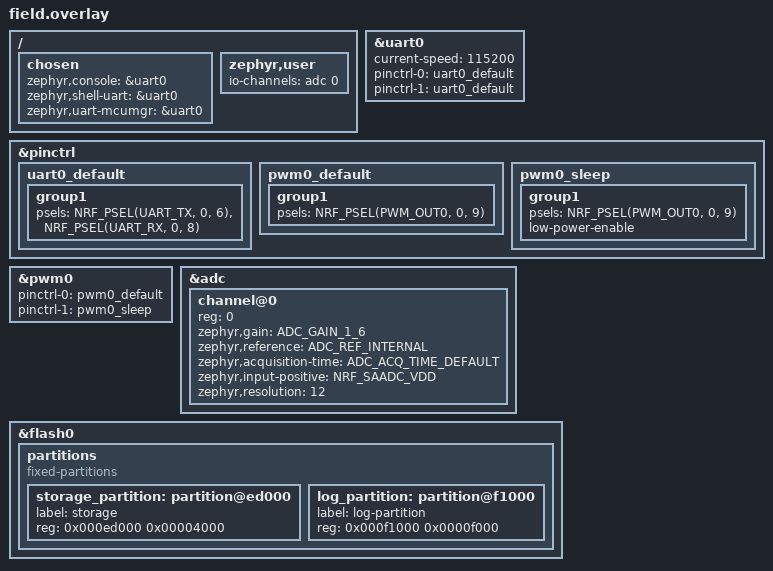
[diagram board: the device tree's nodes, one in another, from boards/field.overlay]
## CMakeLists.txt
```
cmake_minimum_required(VERSION 3.20.0)
find_package(Zephyr REQUIRED HINTS $ENV{ZEPHYR_BASE})
project(reed_sensor)

target_sources(app PRIVATE
    src/main.c
    src/reed_hw_zephyr.c
    src/ble_adv.c
    src/battery.c
    src/build_info.c
    src/trinity_wdt.c
    src/trinity_canary.c
    src/trinity_flash.c
    src/trinity_stats.c
    src/trinity_fault.c
    src/trinity_boot.c
    drivers/fuel_gauge/max17048/max17048.c
)

target_include_directories(app PRIVATE
    drivers/fuel_gauge/max17048
    ../../include
)
```

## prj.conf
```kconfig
# /******************************************************************************
# * \file prj.conf
# * \author MichaelLynnCSU (https://github.com/MichaelLynnCSU)
# * \date    01-01-2025
# *
# * \brief   Zephyr project configuration for nRF52840 reed sensor node.
# *
# * \details Enables GPIO, ADC, UART console, deferred logging, BLE
# *          broadcaster/observer, flash storage, UF2 build output,
# *          stack sentinel, and heap checking for trinity fault coverage.
# *
# *          Trinity build mode is selected at west build time:
# *            BENCH: west build -- -DCONFIG_TRINITY_MODE_BENCH=y
# *            FIELD: west build (default — no extra flag needed)
# ******************************************************************************/

# ========================= CORE PERIPHERALS ==================================
CONFIG_GPIO=y
CONFIG_ADC=y
CONFIG_PRINTK=y

# ========================= CONSOLE / UART ====================================
CONFIG_CONSOLE=y
CONFIG_UART_CONSOLE=y
CONFIG_UART_INTERRUPT_DRIVEN=y

# ========================= LOGGING ===========================================
CONFIG_LOG=y
CONFIG_LOG_BACKEND_UART=y
CONFIG_LOG_MODE_DEFERRED=y
CONFIG_LOG_DEFAULT_LEVEL=3
CONFIG_LOG_BUFFER_SIZE=16384
CONFIG_BT_LOG_LEVEL_OFF=y

# ========================= BLUETOOTH =========================================
CONFIG_BT=y
CONFIG_BT_PERIPHERAL=y
CONFIG_BT_BROADCASTER=y
CONFIG_BT_OBSERVER=y
CONFIG_BT_SMP=y
CONFIG_BT_PRIVACY=n
CONFIG_BT_GATT_SERVICE_CHANGED=n
CONFIG_BT_DEVICE_NAME="ReedSensor"

# ========================= FLASH STORAGE =====================================
CONFIG_FLASH=y
CONFIG_FLASH_MAP=y
CONFIG_FLASH_PAGE_LAYOUT=y
CONFIG_MPU_ALLOW_FLASH_WRITE=y
CONFIG_STREAM_FLASH=y

# ========================= BUILD OUTPUT ======================================
CONFIG_BUILD_OUTPUT_UF2=y

# ========================= PERSISTENT SETTINGS ===============================
CONFIG_BT_SETTINGS=y
CONFIG_NVS=y
CONFIG_SETTINGS=y
CONFIG_SETTINGS_NVS=y

# ========================= FAULT COVERAGE ====================================
CONFIG_REBOOT=y
CONFIG_FAULT_DUMP=2
CONFIG_FRAME_POINTER=y
CONFIG_HW_STACK_PROTECTION=y
CONFIG_HEAP_MEM_POOL_IGNORE_MIN=y
CONFIG_THREAD_STACK_INFO=y
CONFIG_THREAD_NAME=y
CONFIG_INIT_STACKS=y

# ========================= RADIO / FLASH SYNC ================================
CONFIG_SOC_FLASH_NRF_RADIO_SYNC_TICKER=y

# ========================= TRINITY WATCHDOG ==================================
CONFIG_WATCHDOG=y
CONFIG_WDT_DISABLE_AT_BOOT=n

# ========================= TRINITY HEAP STATS ================================
CONFIG_SYS_HEAP_RUNTIME_STATS=y
CONFIG_HEAP_MEM_POOL_SIZE=4096
CONFIG_HEAP_MEM_POOL_IGNORE_MIN=y

# ========================= TRINITY THREAD STATS ==============================
CONFIG_THREAD_ANALYZER=y
CONFIG_THREAD_ANALYZER_USE_PRINTK=n
CONFIG_THREAD_ANALYZER_AUTO=n
CONFIG_THREAD_RUNTIME_STATS=y

# ========================= STACK SIZES =======================================
CONFIG_SYSTEM_WORKQUEUE_STACK_SIZE=3072
CONFIG_MAIN_STACK_SIZE=2048
CONFIG_ISR_STACK_SIZE=4096
CONFIG_BOOT_DELAY=2000
CONFIG_LOG_PROCESS_THREAD_STACK_SIZE=2048

# ========================= I2C / FUEL GAUGE ==================================
CONFIG_I2C=y
CONFIG_I2C_NRFX=y
CONFIG_FUEL_GAUGE=y
CONFIG_MAX17048=n
CONFIG_MAX17048=n
```

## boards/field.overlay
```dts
/*******************************************************************************
 * \file field.overlay
 * \author MichaelLynnCSU (https://github.com/MichaelLynnCSU)
 * \date 01-01-2025
 *
 * \brief Field mode devicetree overlay for Pro Micro nRF52840 reed sensor.
 *
 * \details Configures UART console on P0.06/P0.08. Battery measurement
 *          handled by MAX17048 fuel gauge IC over I2C. See
 *          promicro_nrf52840.overlay for full SAADC failure history.
 *
 * \note    Enable pin removed (2026-03-29):
 *          P0.29 vbat-div-en node removed. Pin was wired to P0.31 not
 *          Vbat and had no effect.
 *
 * \note    BATTERY ADC HISTORY (2026-04-22):
 *          All SAADC-based battery measurement approaches failed on this
 *          board due to the HX3001 LDO permanently separating the CR2032
 *          from VDD. Four approaches tested -- see promicro_nrf52840.overlay
 *          for complete failure analysis. Current solution is MAX17048
 *          fuel gauge IC measuring B+ directly over I2C.
 *
 *          Short summary of what was tried and why it failed:
 *          - Divider + AIN:      worked but attenuated a voltage already
 *                                in range. Retained as fallback only.
 *          - Direct AIN:         CR2032 impedance (10-30 ohm) collapses
 *                                under SAADC input capacitance load.
 *          - NRF_SAADC_VDD:      reads 2.5V regulated rail, not cell.
 *          - Direct AIN + caps:  2x 10uF insufficient. CR2032 cannot
 *                                recharge caps fast enough. Datasheet cap
 *                                recommendation assumes low-impedance source,
 *                                not CR2032. Hundreds of uF would be needed.
 *                                Radio state is not the determining factor --
 *                                fails with radio idle too.
 *******************************************************************************/
/delete-node/ &storage_partition;

/ {
    chosen {
        zephyr,console = &uart0;
        zephyr,shell-uart = &uart0;
        zephyr,uart-mcumgr = &uart0;
    };

    zephyr,user {
        io-channels = <&adc 0>;
    };
};

&uart0 {
    status = "okay";
    current-speed = <115200>;
    pinctrl-0 = <&uart0_default>;
    pinctrl-1 = <&uart0_default>;
    pinctrl-names = "default", "sleep";
};

&pinctrl {
    uart0_default: uart0_default {
        group1 {
            psels = <NRF_PSEL(UART_TX, 0, 6)>,
                    <NRF_PSEL(UART_RX, 0, 8)>;
        };
    };
    pwm0_default: pwm0_default {
        group1 {
            psels = <NRF_PSEL(PWM_OUT0, 0, 9)>;
        };
    };
    pwm0_sleep: pwm0_sleep {
        group1 {
            psels = <NRF_PSEL(PWM_OUT0, 0, 9)>;
            low-power-enable;
        };
    };
};

&pwm0 {
    status = "okay";
    pinctrl-0 = <&pwm0_default>;
    pinctrl-1 = <&pwm0_sleep>;
    pinctrl-names = "default", "sleep";
};

&adc {
    status = "okay";
    #address-cells = <1>;
    #size-cells = <0>;
    channel@0 {
        reg = <0>;
        zephyr,gain = "ADC_GAIN_1_6";
        zephyr,reference = "ADC_REF_INTERNAL";
        zephyr,acquisition-time = <ADC_ACQ_TIME_DEFAULT>;
        zephyr,input-positive = <NRF_SAADC_VDD>; /* reads regulated 2.5V rail --
                                                     retained for reference only,
                                                     MAX17048 handles cell measurement */
        zephyr,resolution = <12>;
    };
};

&flash0 {
    partitions {
        compatible = "fixed-partitions";
        #address-cells = <1>;
        #size-cells = <1>;
        storage_partition: partition@ed000 {
            label = "storage";
            reg = <0x000ed000 0x00004000>;
        };
        log_partition: partition@f1000 {
            label = "log-partition";
            reg = <0x000f1000 0x0000f000>;
        };
    };
};
```

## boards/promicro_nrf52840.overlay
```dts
/*******************************************************************************
 * \file promicro_nrf52840.overlay
 * \author MichaelLynnCSU (https://github.com/MichaelLynnCSU)
 * \date 01-01-2025
 *
 * \brief Devicetree overlay for Pro Micro nRF52840 reed sensor node.
 *
 * \details Configures:
 *          - ADC channel 0: VDD internal monitor, 12-bit, 1/6 gain
 *          - UART0: TX=P0.06, RX=P0.08 (overrides board default P0.09/P0.10)
 *          - Flash partitions:
 *            storage_partition @ 0xED000 (16KB) NVS settings
 *            log_partition     @ 0xF1000 (16KB) flash event log
 *
 * \warning Deletes the default storage_partition and redefines it
 *          alongside log_partition in the upper flash region.
 *
 * \note    UART pin override (2026-03-29):
 *          Board default (promicro_nrf52840-pinctrl.dtsi) is TX=P0.09,
 *          RX=P0.10. Overridden here to TX=P0.06, RX=P0.08 to match
 *          the physical header pins used on this node. Override uses
 *          direct node reference (&uart0_default) instead of wrapping
 *          in &pinctrl {} -- the wrapper caused duplicate label conflicts
 *          with the board dtsi, leaving both pin sets active and the
 *          board defaults winning.
 *
 * \note    BATTERY ADC HISTORY -- DO NOT RETRY THESE APPROACHES (2026-04-22):
 *          This board (Teyleten Robot Pro Micro nRF52840) has a HX3001 LDO
 *          regulator permanently in the power path. CR2032 (3V) → HX3001
 *          → 2.5V VDD. The LDO output is always 2.5V regardless of cell
 *          state. SWD connection does not affect this.
 *
 *          Four SAADC approaches were tested and failed:
 *
 *          TEST 1 -- P0.02 (AIN0) + 200k/100k divider:
 *          Worked but nonsensical. CR2032 max voltage (3V) is already within
 *          SAADC range (3.6V at ADC_GAIN_1_6). Divider attenuated a voltage
 *          that needed no attenuation, wasted resolution, added quiescent
 *          drain. Abandoned in favour of direct connection.
 *          NOTE: This is the only SAADC approach that produced stable
 *          readings. It remains the fallback if MAX17048 is unavailable.
 *
 *          TEST 2 -- P0.02 (AIN0) direct, no divider, no caps:
 *          Failed. CR2032 internal impedance (10-30 ohms) cannot source
 *          the SAADC input capacitance charge current fast enough. Rail
 *          collapses during sampling. Longer acquisition time (40us tested)
 *          made it worse -- more time connected means more charge drawn,
 *          deeper voltage sag. Fails even pre-BLE with radio fully idle.
 *
 *          TEST 3 -- NRF_SAADC_VDD internal monitor:
 *          Failed. NRF_SAADC_VDD measures the VDD rail (2.5V regulated),
 *          not the cell. Nordic recommendation assumes cell IS VDD (no
 *          regulator in path). That assumption does not hold on this board.
 *          Always reads ~1812 mV regardless of cell state.
 *
 *          TEST 4 -- P0.02 (AIN0) direct + 2x 10uF bulk caps:
 *          Failed. Datasheet cap recommendation assumes low-impedance source
 *          (Li-ion, LiPo). CR2032 at 10-30 ohms cannot recharge caps fast
 *          enough between samples. Hundreds of uF would be required --
 *          impractical for a coin cell node. Fails with radio idle and
 *          active. Radio state is not the determining factor.
 *
 *          CURRENT SOLUTION -- MAX17048 fuel gauge IC over I2C:
 *          Measures B+ directly with nanoamp bias current. Independent of
 *          VDD rail, SAADC, and BLE radio. See battery.c for implementation.
 *******************************************************************************/
/delete-node/ &storage_partition;
/ {
    zephyr,user {
        io-channels = <&adc 0>;
    };
};
&uart0_default {
    group1 {
        psels = <NRF_PSEL(UART_TX, 0, 6)>,
                <NRF_PSEL(UART_RX, 0, 8)>;
    };
};
&uart0_sleep {
    group1 {
        psels = <NRF_PSEL(UART_TX, 0, 6)>,
                <NRF_PSEL(UART_RX, 0, 8)>;
        low-power-enable;
    };
};
&adc {
    status = "okay";
    #address-cells = <1>;
    #size-cells = <0>;
    channel@0 {
        reg = <0>;
        zephyr,gain = "ADC_GAIN_1_6";
        zephyr,reference = "ADC_REF_INTERNAL";
        zephyr,acquisition-time = <ADC_ACQ_TIME_DEFAULT>;
        zephyr,input-positive = <NRF_SAADC_VDD>; /* reads regulated 2.5V rail --
                                                     retained for reference only,
                                                     MAX17048 handles cell measurement */
        zephyr,resolution = <12>;
    };
};
&flash0 {
    partitions {
        compatible = "fixed-partitions";
        #address-cells = <1>;
        #size-cells = <1>;
        storage_partition: partition@ed000 {
            label = "storage";
            reg = <0x000ed000 0x00004000>;
        };
        log_partition: partition@f1000 {
            label = "log-partition";
            reg = <0x000f1000 0x00004000>;
        };
    };
};
&uart0 {
    status = "okay";
    current-speed = <115200>;
};
```

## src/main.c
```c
/******************************************************************************
 * \file    main.c
 * \author  MichaelLynnCSU (https://github.com/MichaelLynnCSU)
 * \date    01-01-2025
 *
 * \brief   Reed sensor node entry point for door/window state monitoring.
 *
 * \details Monitors a reed switch via GPIO interrupt and broadcasts
 *          open/closed state over BLE manufacturer data advertisements.
 *          Battery SOC is included in the advertisement payload and
 *          updated every 5 minutes.
 *
 *          Hardware:
 *          - Board:    Pro Micro nRF52840
 *          - Reed pin: GPIO0 pin 11 (active-low, pull-up)
 *          - LED:      DT alias led0
 *          - Battery:  MAX17048 fuel gauge over I2C1 (P1.13 SDA, P1.15 SCL)
 *
 * \note    WDT fix (2026-03-21):
 *          REED_POLL_MS reduced from 10000ms to 2000ms. trinity_wdt_kick()
 *          called before sem_take so WDT is fed even when reed is stable.
 *
 * \note    WDT boot-feed fix (2026-03-22):
 *          Progressive WDT feeding at each boot checkpoint. bt_enable()
 *          and settings_load() can each consume up to 2s of the 3s budget.
 *
 * \note    RESETREAS clear fix (2026-03-27):
 *          RESETREAS read and cleared at very top of main() before any
 *          other code runs. Register is latched OR-history -- must be
 *          explicitly cleared to prevent stale bits surviving across boots.
 *
 * \note    Battery read before BLE (2026-04-22, updated 2026-05-01):
 *          battery_read_soc() called before bt_enable() while VDD is
 *          stable. bt_enable() current spike collapses CR2032 rail and
 *          corrupts SAADC reading. Pre-populated into g_mfg_data via
 *          ble_adv_set_batt() so BLE thread uses it directly. With
 *          MAX17048 the rail collapse is less critical (fuel gauge is
 *          independent of SAADC) but the ordering is retained to ensure
 *          the first advertisement always carries a valid SOC.
 *
 * \note    Battery divider removed (2026-04-22):
 *          Resistor divider physically removed. Vbat connects directly
 *          to P0.02 (AIN0). CR2032 3.0V is within ADC_GAIN_1_6 max
 *          input of 3.6V. No quiescent divider drain.
 ******************************************************************************/

#include <zephyr/kernel.h>
#include <zephyr/drivers/gpio.h>
#include <zephyr/logging/log.h>
#include <nrf.h>
#include <string.h>
#include "reed_hw.h"
#include "ble_adv.h"
#include "battery.h"
#include "trinity_log.h"
#include "main.h"

LOG_MODULE_REGISTER(reed_main, LOG_LEVEL_INF);

#define BLE_STACK_SIZE   4096
#define BLE_PRIORITY     5
#define REED_DEBOUNCE_MS 50

K_SEM_DEFINE(g_reed_changed_sem, 0, 1);

static struct gpio_callback g_reed_cb_data;
static const struct device *g_gpio0_int;

/*----------------------------------------------------------------------------*/

static void reed_interrupt_handler(const struct device *p_dev,
                                    struct gpio_callback *p_cb,
                                    uint32_t pins)
{
    (void)p_dev;
    (void)p_cb;
    (void)pins;

    k_sem_give(&g_reed_changed_sem);
}

/*----------------------------------------------------------------------------*/

static int interrupt_init(void)
{
    int err = 0;

    g_gpio0_int = DEVICE_DT_GET(DT_NODELABEL(gpio0));
    if (!device_is_ready(g_gpio0_int))
    {
        LOG_ERR("GPIO0 not ready for interrupt");
        return -ENODEV;
    }

    err = gpio_pin_interrupt_configure(g_gpio0_int, 11, GPIO_INT_EDGE_BOTH);
    if (0 != err) { LOG_ERR("Reed interrupt configure failed (err=%d)", err); return err; }

    gpio_init_callback(&g_reed_cb_data, reed_interrupt_handler, BIT(11));

    err = gpio_add_callback(g_gpio0_int, &g_reed_cb_data);
    if (0 != err) { LOG_ERR("Reed callback add failed (err=%d)", err); return err; }

    return 0;
}

/*----------------------------------------------------------------------------*/

static void reed_monitor_loop(int last_state)
{
    int     err        = 0;
    int     val        = 0;
    int     batt_tick  = 0;
    int     stats_tick = 0;
    uint8_t cur        = 0;
    uint8_t state      = 0;
    uint8_t soc        = 0;

    while (1)
    {
        trinity_wdt_kick();

        (void)k_sem_take(&g_reed_changed_sem,
                          K_TIMEOUT_ABS_TICKS(
                             k_uptime_ticks() +
                             k_ms_to_ticks_ceil32(REED_POLL_MS)));

        if (++batt_tick >= BATT_UPDATE_TICKS)
        {
            batt_tick = 0;
            soc = battery_read_soc();
            ble_adv_set_batt(soc);
            cur = (uint8_t)reed_hw_read();
            err = k_msgq_put(&g_ble_msgq, &cur, K_NO_WAIT);
            if (0 != err) { LOG_WRN("[BATT] msgq full, drop (err=%d)", err); }
        }

        if (++stats_tick >= STATS_INTERVAL_TICKS)
        {
            stats_tick = 0;
            trinity_log_heap_stats();
            trinity_log_task_stats();
        }

        k_sleep(K_MSEC(REED_DEBOUNCE_MS));

        val = reed_hw_read();
        if (0 > val)
        {
            LOG_WRN("[REED] Pin read failed (err=%d)", val);
        }
        else if (val != last_state)
        {
            LOG_INF("[REED] Changed: %d (%s)", val, val ? "OPEN" : "CLOSED");

            trinity_log_event(val ?
                "EVENT: REED_OPEN\n" : "EVENT: REED_CLOSED\n");

            reed_hw_set_led(!val);

            state = (uint8_t)val;
            err = k_msgq_put(&g_ble_msgq, &state, K_NO_WAIT);
            if (0 != err) { LOG_WRN("[REED] msgq full, drop (err=%d)", err); }

            last_state = val;
        }
    }
}

/*----------------------------------------------------------------------------*/

int main(void)
{
    int      err          = 0;
    int      initial      = 0;
    uint8_t  init_state   = 0;
    uint8_t  soc          = 0;
    uint32_t reset_reason = 0;
    k_tid_t  tid;

    static K_THREAD_STACK_DEFINE(ble_stack, BLE_STACK_SIZE);
    static struct k_thread ble_thread_data;

    reset_reason = NRF_POWER->RESETREAS;
    NRF_POWER->RESETREAS = 0xFFFFFFFF;

#if !defined(CONFIG_TRINITY_MODE_BENCH)
    g_init_stage = TRINITY_STAGE_WDT_INIT;
    trinity_wdt_init();
    trinity_wdt_kick();
#endif

    LOG_INF("=== ReedSensor Boot ===");
    trinity_log_dump_previous();

    if (trinity_log_init() == 0)
    {
        trinity_log_boot_reason(reset_reason);
    }
    trinity_wdt_kick();

    trinity_log_dump_previous_deferred();

#if defined(CONFIG_TRINITY_MODE_BENCH)
    g_init_stage = TRINITY_STAGE_WDT_INIT;
    trinity_wdt_init();
    trinity_wdt_kick();
#endif

    err = reed_hw_init();
    if (0 != err) { return err; }

    err = interrupt_init();
    if (0 != err) { return err; }
    trinity_wdt_kick();

    if (0 != battery_init()) { LOG_WRN("Battery init failed, SOC will read 0"); }
    trinity_wdt_kick();

    soc = battery_read_soc();
    ble_adv_set_batt(soc);
    LOG_INF("Pre-BLE battery mV: %d", battery_read_mv());
    LOG_INF("Pre-BLE battery SOC: %d%%", soc);
    trinity_wdt_kick();

    k_sleep(K_MSEC(100));

    initial = reed_hw_read();
    if (0 > initial) { LOG_ERR("Reed initial read failed (err=%d)", initial); return initial; }

    LOG_INF("Initial state: %d (%s)", initial, initial ? "OPEN" : "CLOSED");

    reed_hw_set_led(initial ? 0 : 1);

    init_state = (uint8_t)initial;
    err = k_msgq_put(&g_ble_msgq, &init_state, K_NO_WAIT);
    if (0 != err) { LOG_WRN("Initial state msgq put failed (err=%d)", err); }

    tid = k_thread_create(&ble_thread_data,
                           ble_stack, BLE_STACK_SIZE,
                           ble_thread,
                           NULL, NULL, NULL,
                           BLE_PRIORITY, 0, K_NO_WAIT);
    if (NULL == tid) { LOG_ERR("BLE thread create failed"); return -ENOMEM; }
    k_thread_name_set(tid, "ble_thread");

    trinity_wdt_kick();

    LOG_INF("BLE thread spawned");
    LOG_INF("Monitoring reed switch");

    reed_monitor_loop(initial);

    return 0;
}
```

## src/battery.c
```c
/******************************************************************************
 * \file battery.c
 * \author MichaelLynnCSU (https://github.com/MichaelLynnCSU)
 * \date 01-01-2025
 *
 * \brief Battery measurement for nRF52840 reed sensor node.
 *
 * \details Reads SOC and voltage from MAX17048 fuel gauge over I2C1
 *          (P1.13 SDA, P1.15 SCL). Uses Zephyr fuel_gauge API.
 *          Returns -1 / 0 on error so callers can store NULL in SQLite.
 *          SOC is clamped to 100 -- ModelGauge reports >100% on fresh
 *          cells until the algorithm settles (~few minutes).
 *
 *          Hardware:
 *          - Board:      Teyleten Robot Pro Micro nRF52840
 *          - Fuel gauge: Adafruit MAX17048 breakout (PID 5580)
 *          - I2C bus:    I2C1, nordic,nrf-twim, 100kHz
 *          - SDA:        P1.13 (header pin SDA1)
 *          - SCL:        P1.15 (header pin SCL1)
 *          - Address:    0x36
 *
 * \warning NEXT DEVELOPER -- READ THIS BEFORE CHANGING BATTERY MEASUREMENT.
 *          Five approaches were tested empirically on this exact hardware
 *          before arriving at the working MAX17048 configuration. Do not
 *          re-attempt any of them. They have all been tried and the failure
 *          modes are fully understood.
 *
 * \note    BOARD TOPOLOGY (2026-04-22):
 *          The Teyleten Robot Pro Micro nRF52840 has a HX3001 LDO regulator
 *          permanently in the power path between the coin cell and VDD.
 *          The LDO always outputs 2.5V regardless of cell voltage.
 *          This means:
 *          - NRF_SAADC_VDD always reads ~2.5V (the regulated rail), never
 *            the cell. Useless for battery monitoring.
 *          - AIN pins powered from VDD can still measure B+ directly since
 *            B+ (3V) is within SAADC input range (3.6V max at 1/6 gain).
 *          - There is no software-only path to measure the raw cell voltage
 *            through the regulated VDD rail.
 *          SWD connection does not affect this -- 2.5V is the LDO output,
 *          not a back-powering artifact from the debugger.
 *
 * \note    TEST 1 -- Resistor divider + AIN pin (WORKED, abandoned) (2026-04-22):
 *          200k/100k divider between B+ and P0.02 (AIN0). Divider ratio 1/3
 *          attenuates cell voltage to ~1V for ADC measurement.
 *          Result: Worked. Readings were stable and accurate.
 *          Reason abandoned: The CR2032 nominal voltage (3V) is already within
 *          the SAADC input range (3.6V max at ADC_GAIN_1_6). The divider
 *          attenuated a voltage that never needed attenuation, wasting
 *          resolution and adding ~1uA quiescent drain through the divider.
 *          The divider correction math also adds unnecessary complexity.
 *          NOTE: If all else fails, Test 1 is the fallback. It works.
 *
 * \note    TEST 2 -- Direct AIN pin, no divider, no caps (FAILED) (2026-04-22):
 *          B+ connected directly to P0.02 (AIN0). No divider, no capacitors.
 *          ADC_GAIN_1_6, ADC_REF_INTERNAL, ADC_ACQ_TIME_DEFAULT (10us).
 *          Result: Unstable readings. Cell voltage collapsed during SAADC
 *          sampling, producing artificially low mV values.
 *          Root cause: CR2032 internal impedance is 10-30 ohms (rising as
 *          cell discharges). The SAADC input capacitance requires a current
 *          pulse to charge at sample time. The cell cannot source this current
 *          fast enough through its internal impedance -- rail collapses.
 *          This failure occurs even pre-BLE with the radio fully idle.
 *          Longer acquisition time (40us) made it worse -- more time connected
 *          to source means more charge drawn from the cell, deeper sag.
 *
 * \note    TEST 3 -- NRF_SAADC_VDD internal monitor (FAILED) (2026-04-22):
 *          Switched ADC input to NRF_SAADC_VDD, the nRF52840 internal VDD
 *          monitor. No external pin. Nordic-recommended approach for coin
 *          cell monitoring on nRF52 series.
 *          Result: Always reads ~1812 mV (the regulated 2.5V rail under load),
 *          never the cell voltage. Multimeter confirmed cell at 3V, VDD at
 *          2.5V. NRF_SAADC_VDD measures VDD, not B+. On this board the HX3001
 *          LDO permanently separates the cell from VDD. The Nordic
 *          recommendation assumes the cell IS VDD (no regulator). That
 *          assumption does not hold on this board.
 *
 * \note    TEST 4 -- Direct AIN pin + bulk capacitors (FAILED) (2026-04-22):
 *          Same as Test 2 but with 2x 10uF ceramic caps added across B+/GND
 *          to provide bulk charge reservoir for SAADC sampling.
 *          Result: Still failed. Readings still low and unstable.
 *          Root cause: The datasheet cap recommendation assumes a low-impedance
 *          source (Li-ion, LiPo -- milliohm internal impedance). With a CR2032
 *          at 10-30 ohms internal impedance, the caps cannot recharge fast
 *          enough between samples. The cell charges the caps too slowly to
 *          replenish what the SAADC draws. Hundreds of uF would be required
 *          to hold the rail stable, which is impractical for a coin cell node.
 *          Tested both with BLE active and pre-BLE (radio idle) -- both failed.
 *          Radio state is not the determining factor. Cell impedance is.
 *
 * \note    TEST 5 -- MAX17048 fuel gauge IC, first attempt (FAILED) (2026-05-01):
 *          Adafruit MAX17048 breakout (PID 5580) connected over I2C1.
 *          IC powered via VIN pin, SDA/SCL wired to P1.13/P1.15.
 *          Result: Consistent NACK on address 0x36. Logic analyzer confirmed
 *          address byte transmitted correctly but no ACK returned.
 *          Root cause: On this specific Adafruit board revision, VIN and BAT
 *          are NOT the same net. The MAX17048 CELL pin is only powered through
 *          the BAT net (JST connector). Without battery on CELL, the IC
 *          powers up but refuses all I2C transactions.
 *          Note: The Adafruit datasheet and multiple online sources incorrectly
 *          state that VIN and BAT are tied together. They are not on this
 *          board revision. Confirmed by logic analyzer showing correct address
 *          transmission with consistent NACK, and by multimeter showing VIN
 *          powered but CELL floating.
 *          Additional debugging performed:
 *          - Swapped two brand new ICs -- same result, ruling out faulty IC.
 *          - Tried nordic,nrf-twi vs nordic,nrf-twim -- twim required.
 *          - Tried &pinctrl wrapper vs direct node reference -- direct
 *            node reference required to avoid pin conflict with board dtsi.
 *          - Confirmed pins P1.13/P1.15 correct via logic analyzer.
 *          - Confirmed 100kHz clock-frequency required for stable operation.
 *
 * \note    TEST 6 -- MAX17048 with BAT jumper to VIN (CURRENT IMPLEMENTATION)
 *          (2026-05-01):
 *          Same wiring as Test 5 but with a jumper wire from BAT pad to VIN
 *          pin on the Adafruit breakout, connecting the CELL input to the
 *          CR2032 rail. Logic analyzer immediately showed full I2C transaction:
 *          AW:36 ACK, Data write ACK, AR:36 ACK, Data read ACK, STOP.
 *          SOC reads correctly, clamped to 100% (ModelGauge reports >100%
 *          on fresh cells for a few minutes until algorithm settles).
 *
 * \note    MAX17048 wiring (2026-05-01):
 *          Adafruit breakout PID 5580 -- THIS BOARD REVISION REQUIRES A
 *          JUMPER FROM BAT PAD TO VIN PIN. Without this jumper the CELL
 *          input floats and the IC NACKs all I2C transactions.
 *          VIN  → CR2032 B+ (board VCC rail)
 *          GND  → GND
 *          SDA  → P1.13 (header pin SDA1) -- 10K pullup onboard
 *          SCL  → P1.15 (header pin SCL1) -- 10K pullup onboard
 *          BAT  → jumper to VIN (required -- see Test 5/6 notes above)
 *          ALRT → floating
 *
 * \note    Enable pin removed (2026-03-29):
 *          Original design used P0.29 as a high-side enable switch.
 *          P0.29 was wired through a resistor to P0.31 (AIN7), not to
 *          Vbat, so the enable had no effect. With the enable inactive,
 *          the ADC pin floated and saturated at raw=4095 (3.6V full
 *          scale), producing ghost voltages. Fix: removed enable pin
 *          entirely. No GPIO needed.
 *
 * \note    I2C driver fix (2026-05-01):
 *          Board default for i2c1 is nordic,nrf-twi (legacy interrupt-driven
 *          driver). This must be overridden to nordic,nrf-twim (EasyDMA) in
 *          the overlay. The legacy driver causes NACK on address under BLE
 *          radio activity due to timing conflicts. See promicro_nrf52840.overlay
 *          for the compatible override and pinctrl configuration.
 *          Direct node reference (&i2c1_default / &i2c1_sleep) required --
 *          wrapping in &pinctrl {} causes duplicate label conflicts with the
 *          board dtsi identical to the UART pin issue (2026-03-29).
 ******************************************************************************/

#include "battery.h"
#include <zephyr/kernel.h>
#include <zephyr/drivers/fuel_gauge.h>
#include <zephyr/logging/log.h>
#include "trinity_log.h"

LOG_MODULE_REGISTER(battery, LOG_LEVEL_INF);

#define VBAT_BUF_SIZE   48    /**< vbat log message buffer size */
#define SOC_MAX         100u  /**< clamp -- ModelGauge reports >100 on fresh cells */

static const struct device *g_fg = NULL;

int battery_init(void)
{
   g_fg = DEVICE_DT_GET_ANY(maxim_max17048);

   if (NULL == g_fg)
   {
      LOG_ERR("MAX17048 device not found in DT");
      return -ENODEV;
   }

   if (!device_is_ready(g_fg))
   {
      LOG_ERR("MAX17048 not ready");
      g_fg = NULL;
      return -ENODEV;
   }

   LOG_INF("MAX17048 ready");
   return 0;
}

int battery_read_mv(void)
{
   union fuel_gauge_prop_val val;
   int                       rc = 0;

   if (NULL == g_fg) { return -EIO; }

   rc = fuel_gauge_get_prop(g_fg, FUEL_GAUGE_VOLTAGE, &val);
   if (0 != rc)
   {
      LOG_ERR("MAX17048 voltage read failed (rc=%d)", rc);
      return -EIO;
   }

   /* FUEL_GAUGE_VOLTAGE returns uV -- convert to mV */
   return val.voltage / 1000;
}

uint8_t battery_read_soc(void)
{
   union fuel_gauge_prop_val val;
   int                       rc  = 0;
   char                      buf[VBAT_BUF_SIZE] = {0};
   uint8_t                   soc = 0;

   if (NULL == g_fg) { return 0; }

   rc = fuel_gauge_get_prop(g_fg, FUEL_GAUGE_RELATIVE_STATE_OF_CHARGE, &val);
   if (0 != rc)
   {
      LOG_ERR("MAX17048 SOC read failed (rc=%d)", rc);
      return 0;
   }

   /* Clamp to 100 -- ModelGauge reports >100% on fresh cells until
    * the algorithm settles over the first few minutes of operation. */
   soc = (val.relative_state_of_charge > SOC_MAX) ?
         SOC_MAX : (uint8_t)val.relative_state_of_charge;

   LOG_INF("[BATT] SOC=%d%% mV=%d", soc, battery_read_mv());
   (void)snprintf(buf, sizeof(buf), "EVENT: BATT_SOC %d%%\n", soc);
   trinity_log_event(buf);

   return soc;
}

void battery_print_status(void)
{
   int  mv                 = 0;
   char buf[VBAT_BUF_SIZE] = {0};

   mv = battery_read_mv();
   if (0 > mv) { LOG_ERR("Battery read failed"); return; }

   (void)snprintf(buf, sizeof(buf), "EVENT: BOOT | VBAT: %d mV\n", mv);
   trinity_log_event(buf);
   LOG_INF("VBAT: %d mV", mv);
}
```

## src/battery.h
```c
/******************************************************************************
 * \file battery.h
 * \author MichaelLynnCSU (https://github.com/MichaelLynnCSU)
 * \date 01-01-2025
 *
 * \brief Battery voltage measurement interface for nRF52840 reed sensor.
 *
 * \details Provides VDD voltage reading via the nRF52840 internal SAADC
 *          VDD monitor. No external pin or resistor divider required.
 *          See battery.c for full implementation history.
 ******************************************************************************/

#ifndef INCLUDE_BATTERY_H_
#define INCLUDE_BATTERY_H_

#include <stdint.h>

/* CR2032 voltage range for SOC calculation.
 * BATT_MV_MAX: nominal full cell voltage (3.0V).
 * BATT_MV_MIN: cutoff -- cell considered dead below this level (2.0V).
 * BATT_MV_RANGE: usable window in mV. */
#define BATT_MV_MAX    3000
#define BATT_MV_MIN    2000
#define BATT_MV_RANGE  1000

/**
 * \brief  Map a raw millivolt reading to a SOC percentage (0-100).
 * \param  mv  Cell voltage in millivolts.
 * \return SOC percent clamped to [0, 100].
 */
static inline uint8_t mv_to_soc(int mv)
{
    if (mv >= BATT_MV_MAX) { return 100u; }
    if (mv <= BATT_MV_MIN) { return 0u;   }
    return (uint8_t)((mv - BATT_MV_MIN) * 100 / BATT_MV_RANGE);
}

/** \brief Initialize battery ADC channel.
 *  \return 0 on success, negative errno on failure. */
int battery_init(void);

/** \brief Read battery voltage in millivolts.
 *  \return Voltage in mV on success, -EIO on failure. */
int battery_read_mv(void);

/** \brief Read battery voltage and return SOC percent (0-100).
 *         Logs a warning and returns 0 on read failure.
 *  \return SOC percent. */
uint8_t battery_read_soc(void);

/** \brief Print battery voltage and status to console and flash log. */
void battery_print_status(void);

#endif /* INCLUDE_BATTERY_H_ */
```

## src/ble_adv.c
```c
/******************************************************************************
 * \file    ble_adv.c
 * \author  MichaelLynnCSU (https://github.com/MichaelLynnCSU)
 * \date    01-01-2025
 *
 * \brief   BLE advertising and thread for nRF52840 reed sensor node.
 *
 * \details Slow-interval broadcaster advertisement. Manufacturer data
 *          payload carries lock state (1 byte) and battery SOC (1 byte).
 *
 *          MFG data layout (5 bytes):
 *          [0] = MFG_COMPANY_ID  (0xAB)
 *          [1] = door state      (0=closed, 1=open)
 *          [2] = batt_soc        (0-100%)
 *          [3] = tx_id low byte
 *          [4] = tx_id high byte
 *
 * \note    BLE adv race fix (2026-03-23):
 *          Uses bt_le_adv_update_data() instead of stop/start pattern.
 *          The stop/start pattern raced against the BLE radio ISR
 *          (prepare_cb in lll_adv.c:1041) causing KERNEL_OOPS under
 *          rapid reed toggling. update_data() is atomic -- no race.
 *
 * \note    BLE thread WDT fix (2026-03-23):
 *          ble_thread while(1) uses bounded K_TIMEOUT_ABS_TICKS instead
 *          of K_FOREVER. trinity_wdt_kick() called at top of loop so
 *          WDT is fed even during periods of reed inactivity.
 *
 * \note    Structured event tracing — tx_id (2026-06-16):
 *          s_tx_id is a uint16_t sequence counter incremented on every
 *          call to ble_broadcast(). It is stamped into mfg_data[3..4]
 *          (little-endian) before each advertisement update so the hub
 *          can read it out of the raw payload and log it as tx_id=.
 *
 *          This gives both sides a shared correlation key:
 *            [DEVICE]   tx_id=1844 state=1 batt=87%
 *            [BLE_REED] tx_id=1844 event_id=101 slot=1 state=1 batt=87%
 *
 *          Template note for other device types:
 *          1. Add s_tx_id counter to ble_adv.c (or equivalent).
 *          2. Increment before payload write, not after.
 *          3. Write lo byte to [N], hi byte to [N+1] at end of payload.
 *          4. Log tx_id= in the broadcast log line.
 *          5. Update MFG_DATA_SIZE in main.h (or equivalent header).
 *          6. Hub side: extract with mfg_len >= (N+2) guard, default 0.
 ******************************************************************************/

#include "ble_adv.h"
#include "main.h"
#include "trinity_log.h"
#include <zephyr/bluetooth/bluetooth.h>
#include <zephyr/bluetooth/hci.h>
#include <zephyr/logging/log.h>
#include <zephyr/settings/settings.h>

LOG_MODULE_REGISTER(ble_adv, LOG_LEVEL_INF);

#define HEARTBEAT_INTERVAL_SEC  240

K_MSGQ_DEFINE(g_ble_msgq, sizeof(uint8_t), 8, 4);

static uint8_t   g_mfg_data[MFG_DATA_SIZE] =
    {MFG_COMPANY_ID, 0x00, 0x00, 0x00, 0x00};  /**< [0]=company_id [1]=state [2]=batt [3]=tx_id_lo [4]=tx_id_hi */
static uint16_t  s_tx_id = 0;                   /**< per-broadcast sequence counter — stamped into mfg_data[3..4] */

static struct bt_data g_adv_data[] =
{
    BT_DATA_BYTES(BT_DATA_FLAGS,
        BT_LE_AD_GENERAL | BT_LE_AD_NO_BREDR),
    BT_DATA(BT_DATA_NAME_COMPLETE,
        CONFIG_BT_DEVICE_NAME,
        sizeof(CONFIG_BT_DEVICE_NAME) - 1),
    BT_DATA(BT_DATA_MANUFACTURER_DATA,
        g_mfg_data,
        sizeof(g_mfg_data))
};

static struct bt_le_adv_param g_adv_param =
{
    .id           = BT_ID_DEFAULT,
    .options      = BT_LE_ADV_OPT_USE_IDENTITY,
    .interval_min = BT_GAP_ADV_SLOW_INT_MIN,
    .interval_max = BT_GAP_ADV_SLOW_INT_MAX,
};

/*----------------------------------------------------------------------------*/

static void heartbeat_handler(struct k_timer *p_timer)
{
    int     ret   = 0;
    uint8_t state = 0;

    (void)p_timer;

    /* Re-broadcast current state on heartbeat tick */
    state = g_mfg_data[1];
    ret = k_msgq_put(&g_ble_msgq, &state, K_NO_WAIT);
    if (0 != ret) { LOG_WRN("[HB] msgq full, state drop (err=%d)", ret); }
    else          { LOG_INF("[HB] Sent"); }
}

K_TIMER_DEFINE(g_heartbeat_timer, heartbeat_handler, NULL);

/*----------------------------------------------------------------------------*/

/******************************************************************************
 * \brief Write state and battery SOC into manufacturer data and refresh
 *        advertisement atomically via bt_le_adv_update_data().
 *        Does NOT stop/restart advertiser -- avoids prepare_cb race.
 *
 * \param state     Door state (0=closed, 1=open).
 * \param batt_soc  Battery SOC percent (0-100).
 *
 * \return 0 on success, negative errno on failure.
 *
 * \details Increments s_tx_id before writing payload so every broadcast
 *          carries a unique sequence number. The hub extracts tx_id from
 *          mfg_data[3..4] (little-endian) and logs it alongside event_id
 *          for end-to-end correlation. s_tx_id wraps at 65535 — the hub
 *          treats wrap-around as a new sequence, not an error.
 *
 * \author MichaelLynnCSU (https://github.com/MichaelLynnCSU)
 ******************************************************************************/
int ble_broadcast(uint8_t state, uint8_t batt_soc)
{
    int err = 0;

    s_tx_id++;
    g_mfg_data[1] = state;
    g_mfg_data[2] = batt_soc;
    g_mfg_data[3] = (uint8_t)(s_tx_id & 0x00FF);
    g_mfg_data[4] = (uint8_t)(s_tx_id >> 8);

    err = bt_le_adv_update_data(g_adv_data, ARRAY_SIZE(g_adv_data), NULL, 0);
    if (0 != err)
    {
        LOG_ERR("[BLE] Adv update failed (err=%d)", err);
    }
    else
    {
        LOG_INF("[BLE] tx_id=%u state=%d batt=%d%%", s_tx_id, state, batt_soc);
    }

    return err;
}

/*----------------------------------------------------------------------------*/

void ble_adv_set_batt(uint8_t batt_soc)
{
    g_mfg_data[2] = batt_soc;
}

/*----------------------------------------------------------------------------*/

void ble_thread(void *p_unused1, void *p_unused2, void *p_unused3)
{
    int      err          = 0;
    uint8_t  state        = 0;
    uint32_t update_count = 0;

    (void)p_unused1;
    (void)p_unused2;
    (void)p_unused3;

    LOG_INF("[BLE] Thread started");

    err = bt_enable(NULL);
    if (0 != err) { LOG_ERR("[BLE] Init failed (err=%d)", err); return; }
    trinity_wdt_kick();

    LOG_INF("[BLE] Bluetooth enabled");

    if (IS_ENABLED(CONFIG_BT_SETTINGS))
    {
        err = settings_load();
        if (0 != err) { LOG_WRN("[BLE] Settings load failed (err=%d)", err); }
        trinity_wdt_kick();
    }

    /* Battery already written into g_mfg_data[2] by main() before
     * bt_enable() -- use pre-populated value. Re-reading here would
     * race against the radio and produce low readings on CR2032. */
    LOG_INF("[BLE] Initial batt=%d%%", g_mfg_data[2]);

    err = bt_le_adv_start(&g_adv_param,
                           g_adv_data,
                           ARRAY_SIZE(g_adv_data),
                           NULL, 0);
    if (0 != err) { LOG_ERR("[BLE] Advertising start failed (err=%d)", err); return; }

    LOG_INF("[BLE] Advertising active | %s", CONFIG_BT_DEVICE_NAME);

    k_timer_start(&g_heartbeat_timer,
                  K_SECONDS(HEARTBEAT_INTERVAL_SEC),
                  K_SECONDS(HEARTBEAT_INTERVAL_SEC));

    while (1)
    {
        trinity_wdt_kick();

        (void)k_msgq_get(&g_ble_msgq, &state,
                          K_TIMEOUT_ABS_TICKS(
                             k_uptime_ticks() +
                             k_ms_to_ticks_ceil32(REED_POLL_MS)));

        trinity_wdt_kick();

        update_count++;
        LOG_INF("[BLE] Update #%u state=%d (%s) batt=%d%%",
                update_count, state,
                state ? "OPEN" : "CLOSED",
                g_mfg_data[2]);

        (void)ble_broadcast(state, g_mfg_data[2]);
    }
}
```

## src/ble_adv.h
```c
/******************************************************************************
 * \file    ble_adv.h
 * \author  MichaelLynnCSU (https://github.com/MichaelLynnCSU)
 * \date    01-01-2025
 *
 * \brief   BLE advertising API for nRF52840 reed sensor node.
 *
 * \note    Structured event tracing — tx_id (2026-06-16):
 *          ble_broadcast() now stamps a uint16_t tx_id sequence counter
 *          into mfg_data[3..4] on every call. See ble_adv.c for details.
 ******************************************************************************/
#ifndef BLE_ADV_H
#define BLE_ADV_H
#include <stdint.h>
#include <zephyr/kernel.h>
/**< Message queue shared between reed monitor and BLE thread.
 *   Reed monitor puts state bytes, BLE thread consumes and broadcasts. */
extern struct k_msgq g_ble_msgq;
/**
 * \brief  BLE thread entry point. Enables BT stack, starts slow-interval
 *         broadcaster advertisement, consumes g_ble_msgq and calls
 *         ble_broadcast() on each state change or heartbeat.
 *         Never returns -- run via k_thread_create().
 */
void ble_thread(void *p_unused1, void *p_unused2, void *p_unused3);
/**
 * \brief  Write state and battery SOC into manufacturer data and refresh
 *         advertisement atomically via bt_le_adv_update_data().
 *         Does NOT stop/restart advertiser -- avoids prepare_cb race.
 *         Increments internal s_tx_id counter and stamps it into
 *         mfg_data[3..4] (little-endian) before each update so the hub
 *         can correlate device-side and hub-side logs via tx_id=.
 *
 * \param  state     Door state (0=closed, 1=open).
 * \param  batt_soc  Battery SOC percent (0-100).
 * \return 0 on success, negative errno on failure.
 */
int ble_broadcast(uint8_t state, uint8_t batt_soc);
/**
 * \brief  Write battery SOC directly into manufacturer data payload.
 *         Called from main() before BLE thread starts so the initial
 *         advertisement carries a valid battery reading.
 *
 * \param  batt_soc  Battery SOC percent (0-100).
 */
void ble_adv_set_batt(uint8_t batt_soc);
#endif /* BLE_ADV_H */
```

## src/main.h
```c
#ifndef MAIN_H
#define MAIN_H
#include <stdint.h>
#define BATT_UPDATE_TICKS    150   /**< reed poll ticks between batt reads  */
#define STATS_INTERVAL_TICKS  30   /**< reed poll ticks between stat dumps  */
#define MFG_DATA_SIZE          5   /**< BLE manufacturer data payload bytes
                                    *   [0] = MFG_COMPANY_ID  (0xAB)
                                    *   [1] = door state      (0=closed, 1=open)
                                    *   [2] = batt_soc        (0-100%)
                                    *   [3] = tx_id low byte
                                    *   [4] = tx_id high byte
                                    *
                                    *   tx_id is a uint16_t sequence counter
                                    *   stamped by the device on every broadcast.
                                    *   The hub reads it out of the raw mfg payload
                                    *   and logs it as tx_id= at BLE ingress so
                                    *   device-side and hub-side logs share the same
                                    *   correlation key.
                                    *
                                    *   Graceful degradation: hubs receiving a 3-byte
                                    *   payload from an older firmware default tx_id=0
                                    *   and continue operating normally.
                                    *
                                    *   Template note: when adding tx_id to a new
                                    *   device type, append tx_id_lo and tx_id_hi at
                                    *   the END of the existing payload so old hub
                                    *   firmware that checks mfg_len < 5 degrades
                                    *   cleanly. Never insert tx_id bytes in the
                                    *   middle of an existing layout.           */
#define MFG_COMPANY_ID      0xAB   /**< BLE company ID for reed sensors     */
#define REED_POLL_MS        2000   /**< main loop poll interval ms          */
#endif /* MAIN_H */
```

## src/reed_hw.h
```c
#ifndef REED_HW_H
#define REED_HW_H
/**
 * \brief  Initialise GPIO for reed switch and debug LED.
 * \return 0 on success, negative errno on failure.
 */
int reed_hw_init(void);

/**
 * \brief  Read current reed switch state.
 * \return 1=open, 0=closed, negative errno on failure.
 */
int reed_hw_read(void);

/**
 * \brief  Set debug LED state.
 * \param  state  1=on, 0=off.
 */
void reed_hw_set_led(int state);
#endif /* REED_HW_H */
```

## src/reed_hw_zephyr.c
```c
/******************************************************************************
 * \file    reed_hw_zephyr.c
 * \brief   Zephyr GPIO binding for reed switch and debug LED.
 *
 * \details Implements reed_hw.h using Zephyr GPIO API.
 *          All Zephyr driver includes are isolated here.
 *          main.c calls through reed_hw.h and has no GPIO dependency.
 ******************************************************************************/

#include "reed_hw.h"
#include <zephyr/drivers/gpio.h>
#include <zephyr/devicetree.h>
#include <zephyr/logging/log.h>

LOG_MODULE_DECLARE(reed_main, LOG_LEVEL_INF);

#define LED_NODE  DT_ALIAS(led0)
#define REED_PORT DT_NODELABEL(gpio0)
#define REED_PIN  11

static const struct gpio_dt_spec g_led =
    GPIO_DT_SPEC_GET(LED_NODE, gpios);
static const struct device *g_gpio0;

/*----------------------------------------------------------------------------*/

int reed_hw_init(void)
{
    int err = 0;

    g_gpio0 = DEVICE_DT_GET(REED_PORT);

    if (!device_is_ready(g_gpio0))    { LOG_ERR("GPIO0 not ready");  return -ENODEV; }
    if (!device_is_ready(g_led.port)) { LOG_ERR("LED not ready");    return -ENODEV; }

    err = gpio_pin_configure_dt(&g_led, GPIO_OUTPUT_INACTIVE);
    if (0 != err) { LOG_ERR("LED configure failed (err=%d)", err); return err; }

    err = gpio_pin_configure(g_gpio0, REED_PIN, GPIO_INPUT | GPIO_PULL_UP);
    if (0 != err) { LOG_ERR("Reed pin configure failed (err=%d)", err); return err; }

    return 0;
}

/*----------------------------------------------------------------------------*/

int reed_hw_read(void)
{
    return gpio_pin_get(g_gpio0, REED_PIN);
}

/*----------------------------------------------------------------------------*/

void reed_hw_set_led(int state)
{
    int err = gpio_pin_set_dt(&g_led, state);
    if (0 != err) { LOG_WRN("LED set failed (err=%d)", err); }
}
```
